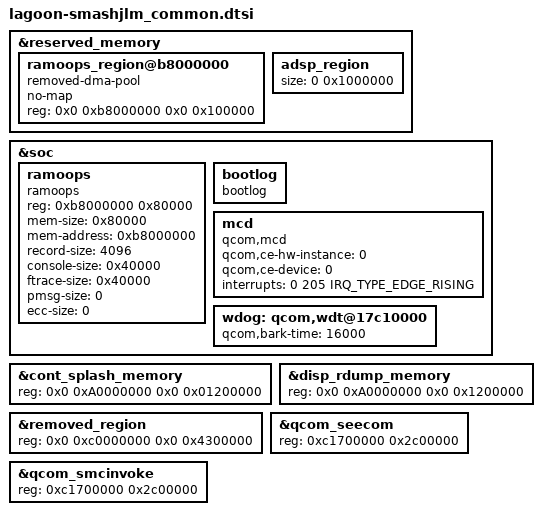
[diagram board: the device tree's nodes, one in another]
// SPDX-License-Identifier: GPL-2.0-only
/*
 * Copyright (c) 2018-2019, The Linux Foundation. All rights reserved.
 */
&reserved_memory {
    ramoops_region@b8000000 {
        compatible = "removed-dma-pool";
        no-map;
        reg = <0x0 0xb8000000 0x0 0x100000>;
    };

    // Increase size to fix ADSPRPC memory allocation fail
    adsp_region {
        size = <0 0x1000000>;
    };

};

&soc {
    ramoops {
        compatible = "ramoops";
        reg = <0xb8000000 0x80000>;
        mem-size = <0x80000>;
        mem-address = <0xb8000000>;
        record-size = <4096>;
        console-size = <0x40000>;
        ftrace-size = <0x40000>;
        pmsg-size = <0>;
        ecc-size = <0>;
    };

    bootlog {
        compatible = "bootlog";
    };

    mcd {
        compatible = "qcom,mcd";
        qcom,ce-hw-instance = <0>;
        qcom,ce-device = <0>;
        interrupts = <0 205 IRQ_TYPE_EDGE_RISING>;
        interrupt-names = "mcd_irq";
    };

    wdog: qcom,wdt@17c10000 {
        qcom,bark-time = <16000>;
    };
};

&cont_splash_memory {
    reg = <0x0 0xA0000000 0x0 0x01200000>;
};

&disp_rdump_memory {
	reg = <0x0 0xA0000000 0x0 0x1200000>;
};

&removed_region{
	reg = <0x0 0xc0000000 0x0 0x4300000>;
};

&qcom_seecom {
        reg = <0xc1700000 0x2c00000>;
};

&qcom_smcinvoke {
        reg = <0xc1700000 0x2c00000>;
};
